AUTOSAR XML (schema 4-0-3)
standard types defined: Boolean, UInt16, UInt8
package /AUTOSAR_Platform/DataConstrs
  range DC_Boolean: raw 0..1
  range DC_UInt16: raw 0..65535
package /PATAC/MSM/ComponentTypes
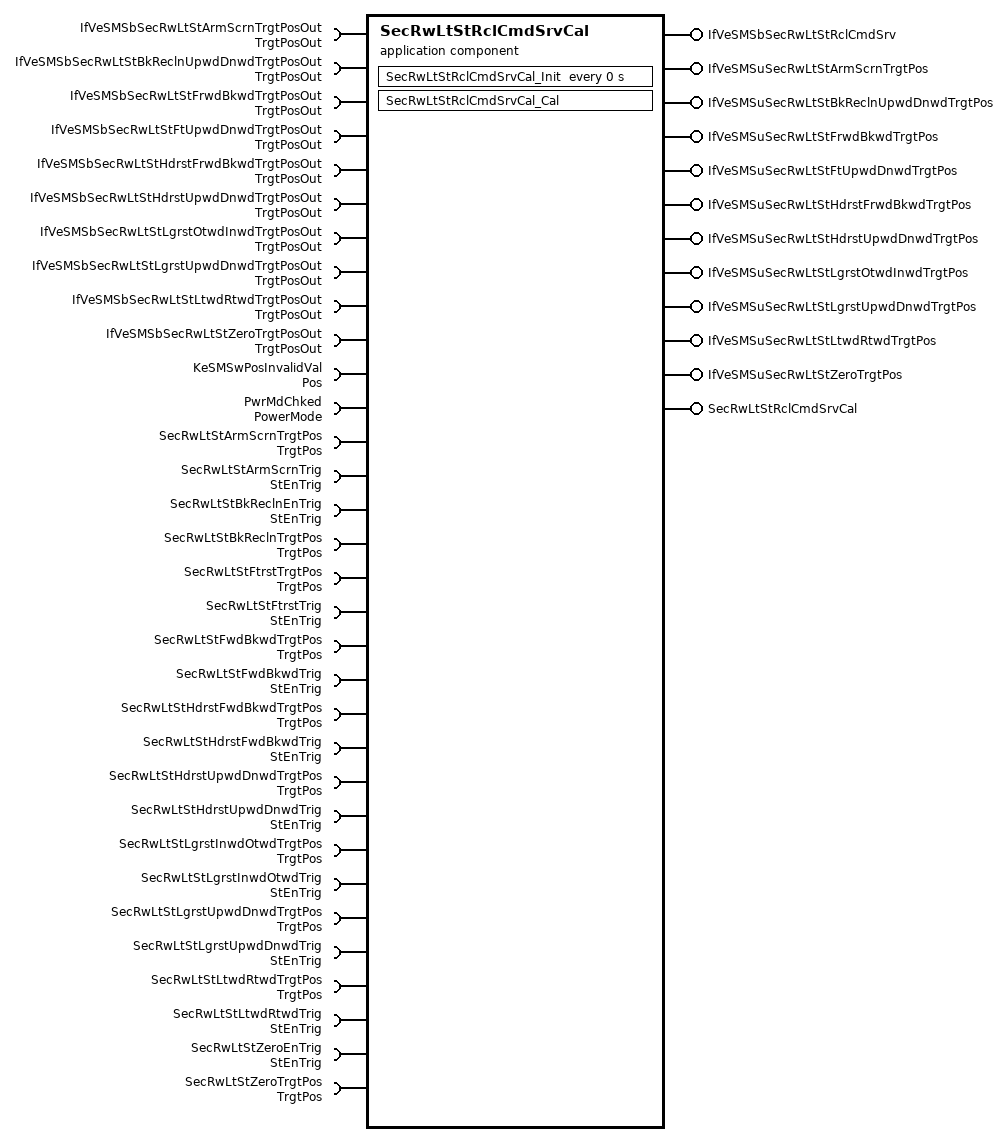
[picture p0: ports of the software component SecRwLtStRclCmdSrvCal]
  application sw component type SecRwLtStRclCmdSrvCal
    12 x provide port:
      IfVeSMSbSecRwLtStRclCmdSrv: nonqueued-sender-com-spec=data-element=IfVeSMSbSecRwLtStRclCmdSrv/Val, provided-interface=IfVeSMSbSecRwLtStRclCmdSrv
      IfVeSMSuSecRwLtStArmScrnTrgtPos: nonqueued-sender-com-spec=data-element=IfVeSMSuSecRwLtStArmScrnTrgtPos/Val, provided-interface=IfVeSMSuSecRwLtStArmScrnTrgtPos
      IfVeSMSuSecRwLtStBkReclnUpwdDnwdTrgtPos: nonqueued-sender-com-spec=data-element=IfVeSMSuSecRwLtStBkReclnUpwdDnwdTrgtPos/Val, provided-interface=IfVeSMSuSecRwLtStBkReclnUpwdDnwdTrgtPos
      IfVeSMSuSecRwLtStFrwdBkwdTrgtPos: nonqueued-sender-com-spec=data-element=IfVeSMSuSecRwLtStFrwdBkwdTrgtPos/Val, provided-interface=IfVeSMSuSecRwLtStFrwdBkwdTrgtPos
      IfVeSMSuSecRwLtStFtUpwdDnwdTrgtPos: nonqueued-sender-com-spec=data-element=IfVeSMSuSecRwLtStFtUpwdDnwdTrgtPos/Val, provided-interface=IfVeSMSuSecRwLtStFtUpwdDnwdTrgtPos
      IfVeSMSuSecRwLtStHdrstFrwdBkwdTrgtPos: nonqueued-sender-com-spec=data-element=IfVeSMSuSecRwLtStHdrstFrwdBkwdTrgtPos/Val, provided-interface=IfVeSMSuSecRwLtStHdrstFrwdBkwdTrgtPos
      IfVeSMSuSecRwLtStHdrstUpwdDnwdTrgtPos: nonqueued-sender-com-spec=data-element=IfVeSMSuSecRwLtStHdrstUpwdDnwdTrgtPos/Val, provided-interface=IfVeSMSuSecRwLtStHdrstUpwdDnwdTrgtPos
      IfVeSMSuSecRwLtStLgrstOtwdInwdTrgtPos: nonqueued-sender-com-spec=data-element=IfVeSMSuSecRwLtStLgrstOtwdInwdTrgtPos/Val, provided-interface=IfVeSMSuSecRwLtStLgrstOtwdInwdTrgtPos
      IfVeSMSuSecRwLtStLgrstUpwdDnwdTrgtPos: nonqueued-sender-com-spec=data-element=IfVeSMSuSecRwLtStLgrstUpwdDnwdTrgtPos/Val, provided-interface=IfVeSMSuSecRwLtStLgrstUpwdDnwdTrgtPos
      IfVeSMSuSecRwLtStLtwdRtwdTrgtPos: nonqueued-sender-com-spec=data-element=IfVeSMSuSecRwLtStLtwdRtwdTrgtPos/Val, provided-interface=IfVeSMSuSecRwLtStLtwdRtwdTrgtPos
      IfVeSMSuSecRwLtStZeroTrgtPos: nonqueued-sender-com-spec=data-element=IfVeSMSuSecRwLtStZeroTrgtPos/Val, provided-interface=IfVeSMSuSecRwLtStZeroTrgtPos
      SecRwLtStRclCmdSrvCal: server-com-spec{operation=Cal, queue-length=1}, provided-interface=SecRwLtStRclCmdSrvCal
    32 x require port:
      IfVeSMSbSecRwLtStArmScrnTrgtPosOut: nonqueued-receiver-com-spec{data-element=TrgtPosOut/Val, filter=data-filter-type=ALWAYS, init-value=0}, required-interface=TrgtPosOut
      IfVeSMSbSecRwLtStBkReclnUpwdDnwdTrgtPosOut: nonqueued-receiver-com-spec{data-element=TrgtPosOut/Val, filter=data-filter-type=ALWAYS, init-value=0}, required-interface=TrgtPosOut
      IfVeSMSbSecRwLtStFrwdBkwdTrgtPosOut: nonqueued-receiver-com-spec{data-element=TrgtPosOut/Val, filter=data-filter-type=ALWAYS, init-value=0}, required-interface=TrgtPosOut
      IfVeSMSbSecRwLtStFtUpwdDnwdTrgtPosOut: nonqueued-receiver-com-spec{data-element=TrgtPosOut/Val, filter=data-filter-type=ALWAYS, init-value=0}, required-interface=TrgtPosOut
      IfVeSMSbSecRwLtStHdrstFrwdBkwdTrgtPosOut: nonqueued-receiver-com-spec{data-element=TrgtPosOut/Val, filter=data-filter-type=ALWAYS, init-value=0}, required-interface=TrgtPosOut
      IfVeSMSbSecRwLtStHdrstUpwdDnwdTrgtPosOut: nonqueued-receiver-com-spec{data-element=TrgtPosOut/Val, filter=data-filter-type=ALWAYS, init-value=0}, required-interface=TrgtPosOut
      IfVeSMSbSecRwLtStLgrstOtwdInwdTrgtPosOut: nonqueued-receiver-com-spec{data-element=TrgtPosOut/Val, filter=data-filter-type=ALWAYS, init-value=0}, required-interface=TrgtPosOut
      IfVeSMSbSecRwLtStLgrstUpwdDnwdTrgtPosOut: nonqueued-receiver-com-spec{data-element=TrgtPosOut/Val, filter=data-filter-type=ALWAYS, init-value=0}, required-interface=TrgtPosOut
      IfVeSMSbSecRwLtStLtwdRtwdTrgtPosOut: nonqueued-receiver-com-spec{data-element=TrgtPosOut/Val, filter=data-filter-type=ALWAYS, init-value=0}, required-interface=TrgtPosOut
      IfVeSMSbSecRwLtStZeroTrgtPosOut: nonqueued-receiver-com-spec{data-element=TrgtPosOut/Val, filter=data-filter-type=ALWAYS, init-value=0}, required-interface=TrgtPosOut
      KeSMSwPosInvalidVal: parameter-require-com-spec{init-value=4095, parameter=Val}, required-interface=Pos
      PwrMdChked: nonqueued-receiver-com-spec{data-element=PowerMode/Val, filter=data-filter-type=ALWAYS, init-value=0}, required-interface=PowerMode
      SecRwLtStArmScrnTrgtPos: nonqueued-receiver-com-spec{data-element=TrgtPos/Val, filter=data-filter-type=ALWAYS, init-value=4095}, required-interface=TrgtPos
      SecRwLtStArmScrnTrig: nonqueued-receiver-com-spec{data-element=StEnTrig/Val, filter=data-filter-type=ALWAYS, init-value=0}, required-interface=StEnTrig
      SecRwLtStBkReclnEnTrig: nonqueued-receiver-com-spec{data-element=StEnTrig/Val, filter=data-filter-type=ALWAYS, init-value=0}, required-interface=StEnTrig
      SecRwLtStBkReclnTrgtPos: nonqueued-receiver-com-spec{data-element=TrgtPos/Val, filter=data-filter-type=ALWAYS, init-value=4095}, required-interface=TrgtPos
      SecRwLtStFtrstTrgtPos: nonqueued-receiver-com-spec{data-element=TrgtPos/Val, filter=data-filter-type=ALWAYS, init-value=4095}, required-interface=TrgtPos
      SecRwLtStFtrstTrig: nonqueued-receiver-com-spec{data-element=StEnTrig/Val, filter=data-filter-type=ALWAYS, init-value=0}, required-interface=StEnTrig
      SecRwLtStFwdBkwdTrgtPos: nonqueued-receiver-com-spec{data-element=TrgtPos/Val, filter=data-filter-type=ALWAYS, init-value=4095}, required-interface=TrgtPos
      SecRwLtStFwdBkwdTrig: nonqueued-receiver-com-spec{data-element=StEnTrig/Val, filter=data-filter-type=ALWAYS, init-value=0}, required-interface=StEnTrig
      SecRwLtStHdrstFwdBkwdTrgtPos: nonqueued-receiver-com-spec{data-element=TrgtPos/Val, filter=data-filter-type=ALWAYS, init-value=4095}, required-interface=TrgtPos
      SecRwLtStHdrstFwdBkwdTrig: nonqueued-receiver-com-spec{data-element=StEnTrig/Val, filter=data-filter-type=ALWAYS, init-value=0}, required-interface=StEnTrig
      SecRwLtStHdrstUpwdDnwdTrgtPos: nonqueued-receiver-com-spec{data-element=TrgtPos/Val, filter=data-filter-type=ALWAYS, init-value=4095}, required-interface=TrgtPos
      SecRwLtStHdrstUpwdDnwdTrig: nonqueued-receiver-com-spec{data-element=StEnTrig/Val, filter=data-filter-type=ALWAYS, init-value=0}, required-interface=StEnTrig
      SecRwLtStLgrstInwdOtwdTrgtPos: nonqueued-receiver-com-spec{data-element=TrgtPos/Val, filter=data-filter-type=ALWAYS, init-value=4095}, required-interface=TrgtPos
      SecRwLtStLgrstInwdOtwdTrig: nonqueued-receiver-com-spec{data-element=StEnTrig/Val, filter=data-filter-type=ALWAYS, init-value=0}, required-interface=StEnTrig
      SecRwLtStLgrstUpwdDnwdTrgtPos: nonqueued-receiver-com-spec{data-element=TrgtPos/Val, filter=data-filter-type=ALWAYS, init-value=4095}, required-interface=TrgtPos
      SecRwLtStLgrstUpwdDnwdTrig: nonqueued-receiver-com-spec{data-element=StEnTrig/Val, filter=data-filter-type=ALWAYS, init-value=0}, required-interface=StEnTrig
      SecRwLtStLtwdRtwdTrgtPos: nonqueued-receiver-com-spec{data-element=TrgtPos/Val, filter=data-filter-type=ALWAYS, init-value=4095}, required-interface=TrgtPos
      SecRwLtStLtwdRtwdTrig: nonqueued-receiver-com-spec{data-element=StEnTrig/Val, filter=data-filter-type=ALWAYS, init-value=0}, required-interface=StEnTrig
      SecRwLtStZeroEnTrig: nonqueued-receiver-com-spec{data-element=StEnTrig/Val, filter=data-filter-type=ALWAYS, init-value=0}, required-interface=StEnTrig
      SecRwLtStZeroTrgtPos: nonqueued-receiver-com-spec{data-element=TrgtPos/Val, filter=data-filter-type=ALWAYS, init-value=4095}, required-interface=TrgtPos
    behavior SecRwLtStRclCmdSrvCal_InternalBehavior
      operation invoked event OIT_SecRwLtStRclCmdSrvCal_Cal_SecRwLtStRclCmdSrvCal_Cal: start-on-event=SecRwLtStRclCmdSrvCal_Cal, operation=SecRwLtStRclCmdSrvCal.Cal
      timing event SecRwLtStRclCmdSrvCal_InitEvent: start-on-event=SecRwLtStRclCmdSrvCal_Init, period=0
      runnable SecRwLtStRclCmdSrvCal_Cal
        data-receive-point-by-arguments:
          31 x access:
            REC_IfVeSMSbSecRwLtStArmScrnTrgtPosOut_Val: accessed-variable=IfVeSMSbSecRwLtStArmScrnTrgtPosOut.Val
            REC_IfVeSMSbSecRwLtStBkReclnUpwdDnwdTrgtPosOut_Val: accessed-variable=IfVeSMSbSecRwLtStBkReclnUpwdDnwdTrgtPosOut.Val
            REC_IfVeSMSbSecRwLtStFrwdBkwdTrgtPosOut_Val: accessed-variable=IfVeSMSbSecRwLtStFrwdBkwdTrgtPosOut.Val
            REC_IfVeSMSbSecRwLtStFtUpwdDnwdTrgtPosOut_Val: accessed-variable=IfVeSMSbSecRwLtStFtUpwdDnwdTrgtPosOut.Val
            REC_IfVeSMSbSecRwLtStHdrstFrwdBkwdTrgtPosOut_Val: accessed-variable=IfVeSMSbSecRwLtStHdrstFrwdBkwdTrgtPosOut.Val
            REC_IfVeSMSbSecRwLtStHdrstUpwdDnwdTrgtPosOut_Val: accessed-variable=IfVeSMSbSecRwLtStHdrstUpwdDnwdTrgtPosOut.Val
            REC_IfVeSMSbSecRwLtStLgrstOtwdInwdTrgtPosOut_Val: accessed-variable=IfVeSMSbSecRwLtStLgrstOtwdInwdTrgtPosOut.Val
            REC_IfVeSMSbSecRwLtStLgrstUpwdDnwdTrgtPosOut_Val: accessed-variable=IfVeSMSbSecRwLtStLgrstUpwdDnwdTrgtPosOut.Val
            REC_IfVeSMSbSecRwLtStLtwdRtwdTrgtPosOut_Val: accessed-variable=IfVeSMSbSecRwLtStLtwdRtwdTrgtPosOut.Val
            REC_IfVeSMSbSecRwLtStZeroTrgtPosOut_Val: accessed-variable=IfVeSMSbSecRwLtStZeroTrgtPosOut.Val
            REC_PwrMdChked_Val: accessed-variable=PwrMdChked.Val
            REC_SecRwLtStArmScrnTrgtPos_Val: accessed-variable=SecRwLtStArmScrnTrgtPos.Val
            REC_SecRwLtStArmScrnTrig_Val: accessed-variable=SecRwLtStArmScrnTrig.Val
            REC_SecRwLtStBkReclnEnTrig_Val: accessed-variable=SecRwLtStBkReclnEnTrig.Val
            REC_SecRwLtStBkReclnTrgtPos_Val: accessed-variable=SecRwLtStBkReclnTrgtPos.Val
            REC_SecRwLtStFtrstTrgtPos_Val: accessed-variable=SecRwLtStFtrstTrgtPos.Val
            REC_SecRwLtStFtrstTrig_Val: accessed-variable=SecRwLtStFtrstTrig.Val
            REC_SecRwLtStFwdBkwdTrgtPos_Val: accessed-variable=SecRwLtStFwdBkwdTrgtPos.Val
            REC_SecRwLtStFwdBkwdTrig_Val: accessed-variable=SecRwLtStFwdBkwdTrig.Val
            REC_SecRwLtStHdrstFwdBkwdTrgtPos_Val: accessed-variable=SecRwLtStHdrstFwdBkwdTrgtPos.Val
            REC_SecRwLtStHdrstFwdBkwdTrig_Val: accessed-variable=SecRwLtStHdrstFwdBkwdTrig.Val
            REC_SecRwLtStHdrstUpwdDnwdTrgtPos_Val: accessed-variable=SecRwLtStHdrstUpwdDnwdTrgtPos.Val
            REC_SecRwLtStHdrstUpwdDnwdTrig_Val: accessed-variable=SecRwLtStHdrstUpwdDnwdTrig.Val
            REC_SecRwLtStLgrstInwdOtwdTrgtPos_Val: accessed-variable=SecRwLtStLgrstInwdOtwdTrgtPos.Val
            REC_SecRwLtStLgrstInwdOtwdTrig_Val: accessed-variable=SecRwLtStLgrstInwdOtwdTrig.Val
            REC_SecRwLtStLgrstUpwdDnwdTrgtPos_Val: accessed-variable=SecRwLtStLgrstUpwdDnwdTrgtPos.Val
            REC_SecRwLtStLgrstUpwdDnwdTrig_Val: accessed-variable=SecRwLtStLgrstUpwdDnwdTrig.Val
            REC_SecRwLtStLtwdRtwdTrgtPos_Val: accessed-variable=SecRwLtStLtwdRtwdTrgtPos.Val
            REC_SecRwLtStLtwdRtwdTrig_Val: accessed-variable=SecRwLtStLtwdRtwdTrig.Val
            REC_SecRwLtStZeroEnTrig_Val: accessed-variable=SecRwLtStZeroEnTrig.Val
            REC_SecRwLtStZeroTrgtPos_Val: accessed-variable=SecRwLtStZeroTrgtPos.Val
        data-send-points:
          11 x access:
            SEND_IfVeSMSbSecRwLtStRclCmdSrv_Val: accessed-variable=IfVeSMSbSecRwLtStRclCmdSrv.Val
            SEND_IfVeSMSuSecRwLtStArmScrnTrgtPos_Val: accessed-variable=IfVeSMSuSecRwLtStArmScrnTrgtPos.Val
            SEND_IfVeSMSuSecRwLtStBkReclnUpwdDnwdTrgtPos_Val: accessed-variable=IfVeSMSuSecRwLtStBkReclnUpwdDnwdTrgtPos.Val
            SEND_IfVeSMSuSecRwLtStFrwdBkwdTrgtPos_Val: accessed-variable=IfVeSMSuSecRwLtStFrwdBkwdTrgtPos.Val
            SEND_IfVeSMSuSecRwLtStFtUpwdDnwdTrgtPos_Val: accessed-variable=IfVeSMSuSecRwLtStFtUpwdDnwdTrgtPos.Val
            SEND_IfVeSMSuSecRwLtStHdrstFrwdBkwdTrgtPos_Val: accessed-variable=IfVeSMSuSecRwLtStHdrstFrwdBkwdTrgtPos.Val
            SEND_IfVeSMSuSecRwLtStHdrstUpwdDnwdTrgtPos_Val: accessed-variable=IfVeSMSuSecRwLtStHdrstUpwdDnwdTrgtPos.Val
            SEND_IfVeSMSuSecRwLtStLgrstOtwdInwdTrgtPos_Val: accessed-variable=IfVeSMSuSecRwLtStLgrstOtwdInwdTrgtPos.Val
            SEND_IfVeSMSuSecRwLtStLgrstUpwdDnwdTrgtPos_Val: accessed-variable=IfVeSMSuSecRwLtStLgrstUpwdDnwdTrgtPos.Val
            SEND_IfVeSMSuSecRwLtStLtwdRtwdTrgtPos_Val: accessed-variable=IfVeSMSuSecRwLtStLtwdRtwdTrgtPos.Val
            SEND_IfVeSMSuSecRwLtStZeroTrgtPos_Val: accessed-variable=IfVeSMSuSecRwLtStZeroTrgtPos.Val
        parameter access PA_KeSMSwPosInvalidVal_Val: accessed-parameter=KeSMSwPosInvalidVal.Val
      runnable SecRwLtStRclCmdSrvCal_Init
        parameter access PA_KeSMSwPosInvalidVal_Val: accessed-parameter=KeSMSwPosInvalidVal.Val
  swc implementation SecRwLtStRclCmdSrvCal_Implementation: behavior=SecRwLtStRclCmdSrvCal_InternalBehavior
    code-descriptors:
      code Default: artifact-descriptors=autosar-engineering-object={short-label=Default, category=SWSRC}
package /PATAC/MSM/DataTypes
  sender receiver interface IfVeSMSuSecRwLtStZeroTrgtPos: invalidation-policy{data-element=IfVeSMSuSecRwLtStZeroTrgtPos/Val, handle-invalid=DONT-INVALIDATE}
    data Val: type=UInt16
package /PATAC/MSM/ModeAdjust/CalPortInterface
  parameter interface Pos
    parameter data prototype Val: sw-calibration-access=READ-WRITE, type=UInt16
package /PATAC/MSM/ModeAdjust/DataType
  impl type PowerMode1: category=VALUE, base-type=UInt8, sw-calibration-access=READ-ONLY, compu {0=PowerMode_Off, 1=PowerMode_Acc, 2=PowerMode_Run, 3=PowerMode_Crank, 4=PowerMode_Invalid}, type-emitter=RTE
package /PATAC/MSM/ModeAdjust/PortInterface
  client server interface SecRwLtStRclCmdSrvCal
    operation Cal
  sender receiver interface PowerMode: invalidation-policy{data-element=PowerMode/Val, handle-invalid=DONT-INVALIDATE}
    data Val: type=PowerMode1
  sender receiver interface StEnTrig: invalidation-policy{data-element=StEnTrig/Val, handle-invalid=DONT-INVALIDATE}
    data Val: type=Boolean
  sender receiver interface TrgtPosOut: invalidation-policy{data-element=TrgtPosOut/Val, handle-invalid=DONT-INVALIDATE}
    data Val: type=Boolean
package /PATAC/MSM/PortInterfaces
  11 x sender receiver interface:
    IfVeSMSbSecRwLtStRclCmdSrv: invalidation-policy{data-element=IfVeSMSbSecRwLtStRclCmdSrv/Val, handle-invalid=DONT-INVALIDATE}
      data Val: type=Boolean
    IfVeSMSuSecRwLtStArmScrnTrgtPos: invalidation-policy{data-element=IfVeSMSuSecRwLtStArmScrnTrgtPos/Val, handle-invalid=DONT-INVALIDATE}
      data Val: type=UInt16
    IfVeSMSuSecRwLtStBkReclnUpwdDnwdTrgtPos: invalidation-policy{data-element=IfVeSMSuSecRwLtStBkReclnUpwdDnwdTrgtPos/Val, handle-invalid=DONT-INVALIDATE}
      data Val: type=UInt16
    IfVeSMSuSecRwLtStFrwdBkwdTrgtPos: invalidation-policy{data-element=IfVeSMSuSecRwLtStFrwdBkwdTrgtPos/Val, handle-invalid=DONT-INVALIDATE}
      data Val: type=UInt16
    IfVeSMSuSecRwLtStFtUpwdDnwdTrgtPos: invalidation-policy{data-element=IfVeSMSuSecRwLtStFtUpwdDnwdTrgtPos/Val, handle-invalid=DONT-INVALIDATE}
      data Val: type=UInt16
    IfVeSMSuSecRwLtStHdrstFrwdBkwdTrgtPos: invalidation-policy{data-element=IfVeSMSuSecRwLtStHdrstFrwdBkwdTrgtPos/Val, handle-invalid=DONT-INVALIDATE}
      data Val: type=UInt16
    IfVeSMSuSecRwLtStHdrstUpwdDnwdTrgtPos: invalidation-policy{data-element=IfVeSMSuSecRwLtStHdrstUpwdDnwdTrgtPos/Val, handle-invalid=DONT-INVALIDATE}
      data Val: type=UInt16
    IfVeSMSuSecRwLtStLgrstOtwdInwdTrgtPos: invalidation-policy{data-element=IfVeSMSuSecRwLtStLgrstOtwdInwdTrgtPos/Val, handle-invalid=DONT-INVALIDATE}
      data Val: type=UInt16
    IfVeSMSuSecRwLtStLgrstUpwdDnwdTrgtPos: invalidation-policy{data-element=IfVeSMSuSecRwLtStLgrstUpwdDnwdTrgtPos/Val, handle-invalid=DONT-INVALIDATE}
      data Val: type=UInt16
    IfVeSMSuSecRwLtStLtwdRtwdTrgtPos: invalidation-policy{data-element=IfVeSMSuSecRwLtStLtwdRtwdTrgtPos/Val, handle-invalid=DONT-INVALIDATE}
      data Val: type=UInt16
    TrgtPos: invalidation-policy{data-element=TrgtPos/Val, handle-invalid=DONT-INVALIDATE}
      data Val: type=UInt16
